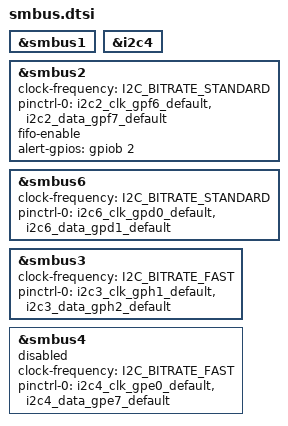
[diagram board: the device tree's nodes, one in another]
/* Copyright 2026 The ChromiumOS Authors
 * Use of this source code is governed by a BSD-style license that can be
 * found in the LICENSE file.
 */

&smbus1 {
	/delete-property/ fifo-enable;   /* FIFO2 */
};

&i2c4 {
	/delete-property/ fifo-enable;   /* FIFO2 */
};

&smbus2 {
	status = "okay";
	clock-frequency = <I2C_BITRATE_STANDARD>;

	pinctrl-0 = <&i2c2_clk_gpf6_default
		     &i2c2_data_gpf7_default>;
	pinctrl-names = "default";
	fifo-enable;

	alert-gpios = <&gpiob 2 0>; /* SMB_INT# */
};

&smbus6 {
	status = "okay";
	clock-frequency = <I2C_BITRATE_STANDARD>;

	pinctrl-0 = <&i2c6_clk_gpd0_default
		     &i2c6_data_gpd1_default>;
	pinctrl-names = "default";
	/delete-property/ fifo-enable;
};

&smbus3 {
	status = "okay";
	clock-frequency = <I2C_BITRATE_FAST>;

	pinctrl-0 = <&i2c3_clk_gph1_default
		     &i2c3_data_gph2_default>;
	pinctrl-names = "default";
	/delete-property/ fifo-enable;
};

&smbus4 {
	status = "disabled";
	clock-frequency = <I2C_BITRATE_FAST>;

	pinctrl-0 = <&i2c4_clk_gpe0_default
		     &i2c4_data_gpe7_default>;
	pinctrl-names = "default";

};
